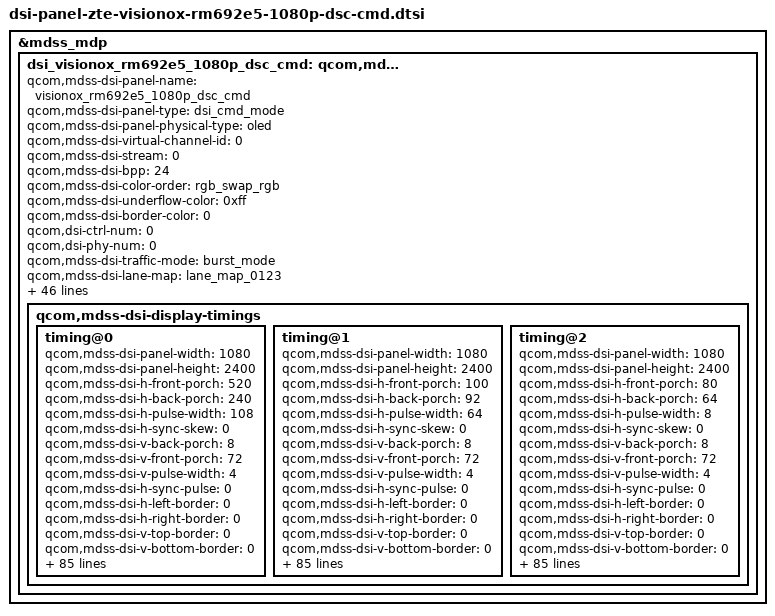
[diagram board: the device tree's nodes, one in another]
&mdss_mdp {
	dsi_visionox_rm692e5_1080p_dsc_cmd: qcom,mdss_dsi_visionox_rm692e5_1080p_dsc_cmd {
		qcom,mdss-dsi-panel-name =
				"visionox_rm692e5_1080p_dsc_cmd";
		qcom,mdss-dsi-panel-type = "dsi_cmd_mode";
		qcom,mdss-dsi-panel-physical-type = "oled";
		qcom,mdss-dsi-virtual-channel-id = <0>;
		qcom,mdss-dsi-stream = <0>;
		qcom,mdss-dsi-bpp = <24>;
		qcom,mdss-dsi-color-order = "rgb_swap_rgb";
		qcom,mdss-dsi-underflow-color = <0xff>;
		qcom,mdss-dsi-border-color = <0>;
		qcom,dsi-ctrl-num = <0>;
		qcom,dsi-phy-num = <0>;
		qcom,mdss-dsi-traffic-mode = "burst_mode";
		qcom,mdss-dsi-lane-map = "lane_map_0123";
		qcom,mdss-dsi-bllp-eof-power-mode;
		qcom,mdss-dsi-bllp-power-mode;
		qcom,mdss-dsi-lane-0-state;
		qcom,mdss-dsi-lane-1-state;
		qcom,mdss-dsi-lane-2-state;
		qcom,mdss-dsi-lane-3-state;
		qcom,mdss-dsi-lp11-init;
		qcom,mdss-dsi-tx-eot-append;
		qcom,mdss-dsi-dma-trigger = "trigger_sw";
		qcom,mdss-dsi-mdp-trigger = "none";
		qcom,mdss-dsi-reset-sequence = <1 10>, <0 10>, <1 50>;
		qcom,mdss-dsi-te-pin-select = <1>;
		qcom,mdss-dsi-te-dcs-command = <1>;
		qcom,mdss-dsi-te-check-enable;
		qcom,mdss-dsi-te-using-te-pin;
		qcom,mdss-dsi-bl-min-level = <1>;
		qcom,mdss-dsi-bl-max-level = <2047>;
		qcom,mdss-dsi-bl-pmic-control-type = "bl_ctrl_dcs";
		qcom,mdss-dsi-panel-hdr-enabled;
		qcom,mdss-dsi-panel-hdr-color-primaries = <14500 15500 34015
			15980 13030 34670 6950 2565>;
		qcom,mdss-dsi-panel-peak-brightness = <6680000>;
		qcom,mdss-dsi-panel-blackness-level = <20>;
		qcom,mdss-pan-physical-width-dimension = <69>;
		qcom,mdss-pan-physical-height-dimension = <155>;
		qcom,bl-dsc-cmd-state = "dsi_lp_mode";
		qcom,mdss-dsi-display-timings {
			timing@0{
				qcom,mdss-dsi-panel-width = <1080>;
				qcom,mdss-dsi-panel-height = <2400>;
				qcom,mdss-dsi-h-front-porch = <520>;
				qcom,mdss-dsi-h-back-porch = <240>;
				qcom,mdss-dsi-h-pulse-width = <108>;
				qcom,mdss-dsi-h-sync-skew = <0>;
				qcom,mdss-dsi-v-back-porch = <8>;
				qcom,mdss-dsi-v-front-porch = <72>;
				qcom,mdss-dsi-v-pulse-width = <4>;
				qcom,mdss-dsi-h-sync-pulse = <0>;
				qcom,mdss-dsi-h-left-border = <0>;
				qcom,mdss-dsi-h-right-border = <0>;
				qcom,mdss-dsi-v-top-border = <0>;
				qcom,mdss-dsi-v-bottom-border = <0>;
				qcom,mdss-dsi-panel-framerate = <60>;
				qcom,mdss-dsi-on-command = [
					/*dynamic elvss for ST IC*/
					15 01 00 00 00 00 02 FE 40
					15 01 00 00 00 00 02 B3 4F
					15 01 00 00 00 00 02 FE 26
					15 01 00 00 00 00 02 18 4C
					15 01 00 00 00 00 02 19 41
					15 01 00 00 00 00 02 A4 21
					15 01 00 00 00 00 02 A5 21
					15 01 00 00 00 00 02 1d 29
					15 01 00 00 00 00 02 FE 41
					15 01 00 00 00 00 02 D6 04
					15 01 00 00 00 00 02 FE 00
					39 01 00 00 00 00 80 77 37 37 37 37 37 37 37 37 39
					   3C 3F 37 37 37 37 37 37 37 37 39 3C 3F 37 37 37
					   37 37 37 37 37 39 3C 3F 37 37 37 37 37 37 37 37
					   39 3C 3F 2B 2B 2B 2B 2B 2B 2B 2B 39 3C 3F 2B 2B
					   2B 2B 2B 2B 2B 2B 39 3C 3F 2B 2B 2B 2B 2B 2B 2B
					   2B 39 3C 3F 2B 2B 2B 2B 2B 2B 2B 2B 39 3C 3F 31
					   31 31 31 31 31 31 31 33 39 3C 31 31 31 31 31 31
					   31 31 33 39 3C 31 31 31 31 31 31 31 31 33 39 3C
					   31 31 31 31 31 31
					39 01 00 00 00 00 80 78 31 31 33 39 3C 2B 2B 2B 2B
    				   2B 2B 2B 2B 33 39 3C 2B 2B 2B 2B 2B 2B 2B 2B 33
					   39 3C 2B 2B 2B 2B 2B 2B 2B 2B 33 39 3C 2B 2B 2B
					   2B 2B 2B 2B 2B 33 39 3C 37 37 37 37 37 37 37 37
					   39 3C 3F 37 37 37 37 37 37 37 37 39 3C 3F 37 37
					   37 37 37 37 37 37 39 3C 3F 37 37 37 37 37 37 37
					   37 39 3C 3F 2B 2B 2B 2B 2B 2B 2B 2B 39 3C 3F 2B
					   2B 2B 2B 2B 2B 2B 2B 39 3C 3F 2B 2B 2B 2B 2B 2B
					   2B 2B 39 3C 3F 2B
					39 01 00 00 00 00 80 78 2B 2B 2B 2B 2B 2B 2B 39 3C
					   3F 31 31 31 31 31 31 31 31 33 39 3C 31 31 31 31
					   31 31 31 31 33 39 3C 31 31 31 31 31 31 31 31 33
					   39 3C 31 31 31 31 31 31 31 31 33 39 3C 2B 2B 2B
					   2B 2B 2B 2B 2B 33 39 3C 2B 2B 2B 2B 2B 2B 2B 2B
					   33 39 3C 2B 2B 2B 2B 2B 2B 2B 2B 33 39 3C 2B 2B
					   2B 2B 2B 2B 2B 2B 33 39 3C 1F 1F 1F 1F 1F 1F 1F
					   1F 21 21 17 1F 1F 1F 1F 1F 1F 1F 1F 21 21 17 1F
					   1F 1F 1F 1F 1F 1F
					39 01 00 00 00 00 80 78 1F 21 21 17 1F 1F 1F 1F 1F
					   1F 1F 1F 21 21 17 1F 1F 1F 1F 1F 1F 1F 1F 21 21
					   17 1F 1F 1F 1F 1F 1F 1F 1F 21 21 17 1F 1F 1F 1F
					   1F 1F 1F 1F 21 21 17 1F 1F 1F 1F 1F 1F 1F 1F 21
					   21 17 1F 1F 1F 1F 1F 1F 1F 1F 21 21 17 1F 1F 1F
					   1F 1F 1F 1F 1F 21 21 17 1F 1F 1F 1F 1F 1F 1F 1F
					   21 21 17 1F 1F 1F 1F 1F 1F 1F 1F 21 21 17 1F 1F
					   1F 1F 1F 1F 1F 1F 21 21 17 1F 1F 1F 1F 1F 1F 1F
					   1F 21 21 17 1F 1F
					39 01 00 00 00 00 15 78 1F 1F 1F 1F 1F 1F 21 21 17
					   1F 1F 1F 1F 1F 1F 1F 1F 21 21 17
					15 01 00 00 00 00 02 FE 41
					15 01 00 00 00 00 02 D6 00
					/* ACL code */
					15 01 00 00 00 00 02 FE 00
					15 01 00 00 00 00 02 55 00
					15 01 00 00 00 00 02 FE 34
					15 01 00 00 00 00 02 47 03
					15 01 00 00 00 00 02 48 00
					15 01 00 00 00 00 02 00 00
					15 01 00 00 00 00 02 FE 34
					15 01 00 00 00 00 02 9F 38
					15 01 00 00 00 00 02 A0 04
					15 01 00 00 00 00 02 1E 00
					15 01 00 00 00 00 02 1F 00
					15 01 00 00 00 00 02 20 00
					15 01 00 00 00 00 02 22 00
					15 01 00 00 00 00 02 21 70
					15 01 00 00 00 00 02 23 F8
					15 01 00 00 00 00 02 24 77
					15 01 00 00 00 00 02 25 F8
					15 01 00 00 00 00 02 26 F8
					15 01 00 00 00 00 02 2F 00
					15 01 00 00 00 00 02 30 00
					15 01 00 00 00 00 02 31 00
					15 01 00 00 00 00 02 32 00
					15 01 00 00 00 00 02 33 00
					15 01 00 00 00 00 02 34 00
					15 01 00 00 00 00 02 35 00
					15 01 00 00 00 00 02 36 4C
					15 01 00 00 00 00 02 37 00
					15 01 00 00 00 00 02 38 E9
					15 01 00 00 00 00 02 39 01
					15 01 00 00 00 00 02 3A 53
					15 01 00 00 00 00 02 3B 00
					15 01 00 00 00 00 02 3D 00
					15 01 00 00 00 00 02 3F 00
					15 01 00 00 00 00 02 40 00
					15 01 00 00 00 00 02 41 00
					15 01 00 00 00 00 02 42 00
					/* P3 */
					15 01 00 00 00 00 02 FE 12
 					15 01 00 00 05 00 02 83 10
					/*init code*/
					15 01 00 00 00 00 02 FE 40
					15 01 00 00 00 00 02 BD 00
					15 01 00 00 00 00 02 FE A1
					15 01 00 00 00 00 02 CD 6B
					15 01 00 00 00 00 02 CE BB
					15 01 00 00 00 00 02 FE D1
					15 01 00 00 00 00 02 B4 01
					15 01 00 00 00 00 02 FE 38
					15 01 00 00 00 00 02 17 0F
					15 01 00 00 00 00 02 18 0F
					15 01 00 00 00 00 02 FE 00
					15 01 00 00 00 00 02 FA 01
					15 01 00 00 00 00 02 C2 08
					15 01 00 00 00 00 02 35 00
					39 01 00 00 00 00 03 51 00 00
					05 01 00 00 50 00 02 11 00
					05 01 00 00 0A 00 02 29 00];
				qcom,mdss-dsi-off-command = [
					05 01 00 00 C8 00 02 28 00
					05 01 00 00 0A 00 02 10 00
				];
				qcom,mdss-dsi-on-command-state = "dsi_lp_mode";
				qcom,mdss-dsi-off-command-state = "dsi_lp_mode";
				qcom,mdss-dsi-lp1-command = [
					15 01 00 00 00 00 02 FE 40
					15 01 00 00 00 00 02 B3 50
					15 01 00 00 00 00 02 FE A0
					15 01 00 00 00 00 02 25 C0
					15 01 00 00 00 00 02 FE 00
					05 01 00 00 00 00 02 39 00
					15 01 00 00 00 00 02 FE 00
				];
				qcom,mdss-dsi-lp1-command-state =
					"dsi_lp_mode";
				qcom,mdss-dsi-nolp-command = [
					39 01 00 00 00 00 02 FE 00
					39 01 00 00 00 00 03 51 00 00
					05 01 00 00 00 00 02 38 00
					39 01 00 00 00 00 02 FE A0
					05 01 00 00 00 00 02 25 40
					39 01 00 00 00 00 02 FE 00
				];
				qcom,mdss-dsi-nolp-command-state =
					"dsi_lp_mode";
				qcom,mdss-dsi-timing-switch-command = [
					15 01 00 00 00 00 02 FE 40
					15 01 00 00 00 00 02 BD 00
					15 01 00 00 00 00 02 FE 00
				];
				qcom,mdss-dsi-timing-switch-command-state =
					"dsi_lp_mode";
				qcom,compression-mode = "dsc";
				qcom,mdss-dsc-slice-height = <20>;
				qcom,mdss-dsc-slice-width = <540>;
				qcom,mdss-dsc-slice-per-pkt = <2>;
				qcom,mdss-dsc-bit-per-component = <8>;
				qcom,mdss-dsc-bit-per-pixel = <8>;
				qcom,mdss-dsc-block-prediction-enable;
			};
			timing@1{
				qcom,mdss-dsi-panel-width = <1080>;
				qcom,mdss-dsi-panel-height = <2400>;
				qcom,mdss-dsi-h-front-porch = <100>;
				qcom,mdss-dsi-h-back-porch = <92>;
				qcom,mdss-dsi-h-pulse-width = <64>;
				qcom,mdss-dsi-h-sync-skew = <0>;
				qcom,mdss-dsi-v-back-porch = <8>;
				qcom,mdss-dsi-v-front-porch = <72>;
				qcom,mdss-dsi-v-pulse-width = <4>;
				qcom,mdss-dsi-h-sync-pulse = <0>;
				qcom,mdss-dsi-h-left-border = <0>;
				qcom,mdss-dsi-h-right-border = <0>;
				qcom,mdss-dsi-v-top-border = <0>;
				qcom,mdss-dsi-v-bottom-border = <0>;
				qcom,mdss-dsi-panel-framerate = <120>;
				qcom,mdss-dsi-on-command = [
					/*dynamic elvss for ST IC*/
					15 01 00 00 00 00 02 FE 40
					15 01 00 00 00 00 02 B3 4F
					15 01 00 00 00 00 02 FE 26
					15 01 00 00 00 00 02 18 4C
					15 01 00 00 00 00 02 19 41
					15 01 00 00 00 00 02 A4 21
					15 01 00 00 00 00 02 A5 21
					15 01 00 00 00 00 02 1d 29
					15 01 00 00 00 00 02 FE 41
					15 01 00 00 00 00 02 D6 04
					15 01 00 00 00 00 02 FE 00
					39 01 00 00 00 00 80 77 37 37 37 37 37 37 37 37 39
					   3C 3F 37 37 37 37 37 37 37 37 39 3C 3F 37 37 37
					   37 37 37 37 37 39 3C 3F 37 37 37 37 37 37 37 37
					   39 3C 3F 2B 2B 2B 2B 2B 2B 2B 2B 39 3C 3F 2B 2B
					   2B 2B 2B 2B 2B 2B 39 3C 3F 2B 2B 2B 2B 2B 2B 2B
					   2B 39 3C 3F 2B 2B 2B 2B 2B 2B 2B 2B 39 3C 3F 31
					   31 31 31 31 31 31 31 33 39 3C 31 31 31 31 31 31
					   31 31 33 39 3C 31 31 31 31 31 31 31 31 33 39 3C
					   31 31 31 31 31 31
					39 01 00 00 00 00 80 78 31 31 33 39 3C 2B 2B 2B 2B
    				   2B 2B 2B 2B 33 39 3C 2B 2B 2B 2B 2B 2B 2B 2B 33
					   39 3C 2B 2B 2B 2B 2B 2B 2B 2B 33 39 3C 2B 2B 2B
					   2B 2B 2B 2B 2B 33 39 3C 37 37 37 37 37 37 37 37
					   39 3C 3F 37 37 37 37 37 37 37 37 39 3C 3F 37 37
					   37 37 37 37 37 37 39 3C 3F 37 37 37 37 37 37 37
					   37 39 3C 3F 2B 2B 2B 2B 2B 2B 2B 2B 39 3C 3F 2B
					   2B 2B 2B 2B 2B 2B 2B 39 3C 3F 2B 2B 2B 2B 2B 2B
					   2B 2B 39 3C 3F 2B
					39 01 00 00 00 00 80 78 2B 2B 2B 2B 2B 2B 2B 39 3C
					   3F 31 31 31 31 31 31 31 31 33 39 3C 31 31 31 31
					   31 31 31 31 33 39 3C 31 31 31 31 31 31 31 31 33
					   39 3C 31 31 31 31 31 31 31 31 33 39 3C 2B 2B 2B
					   2B 2B 2B 2B 2B 33 39 3C 2B 2B 2B 2B 2B 2B 2B 2B
					   33 39 3C 2B 2B 2B 2B 2B 2B 2B 2B 33 39 3C 2B 2B
					   2B 2B 2B 2B 2B 2B 33 39 3C 1F 1F 1F 1F 1F 1F 1F
					   1F 21 21 17 1F 1F 1F 1F 1F 1F 1F 1F 21 21 17 1F
					   1F 1F 1F 1F 1F 1F
					39 01 00 00 00 00 80 78 1F 21 21 17 1F 1F 1F 1F 1F
					   1F 1F 1F 21 21 17 1F 1F 1F 1F 1F 1F 1F 1F 21 21
					   17 1F 1F 1F 1F 1F 1F 1F 1F 21 21 17 1F 1F 1F 1F
					   1F 1F 1F 1F 21 21 17 1F 1F 1F 1F 1F 1F 1F 1F 21
					   21 17 1F 1F 1F 1F 1F 1F 1F 1F 21 21 17 1F 1F 1F
					   1F 1F 1F 1F 1F 21 21 17 1F 1F 1F 1F 1F 1F 1F 1F
					   21 21 17 1F 1F 1F 1F 1F 1F 1F 1F 21 21 17 1F 1F
					   1F 1F 1F 1F 1F 1F 21 21 17 1F 1F 1F 1F 1F 1F 1F
					   1F 21 21 17 1F 1F
					39 01 00 00 00 00 15 78 1F 1F 1F 1F 1F 1F 21 21 17
					   1F 1F 1F 1F 1F 1F 1F 1F 21 21 17
					15 01 00 00 00 00 02 FE 41
					15 01 00 00 00 00 02 D6 00
					/* ACL code */
					15 01 00 00 00 00 02 FE 00
					15 01 00 00 00 00 02 55 00
					15 01 00 00 00 00 02 FE 34
					15 01 00 00 00 00 02 47 03
					15 01 00 00 00 00 02 48 00
					15 01 00 00 00 00 02 00 00
					15 01 00 00 00 00 02 FE 34
					15 01 00 00 00 00 02 9F 38
					15 01 00 00 00 00 02 A0 04
					15 01 00 00 00 00 02 1E 00
					15 01 00 00 00 00 02 1F 00
					15 01 00 00 00 00 02 20 00
					15 01 00 00 00 00 02 22 00
					15 01 00 00 00 00 02 21 70
					15 01 00 00 00 00 02 23 F8
					15 01 00 00 00 00 02 24 77
					15 01 00 00 00 00 02 25 F8
					15 01 00 00 00 00 02 26 F8
					15 01 00 00 00 00 02 2F 00
					15 01 00 00 00 00 02 30 00
					15 01 00 00 00 00 02 31 00
					15 01 00 00 00 00 02 32 00
					15 01 00 00 00 00 02 33 00
					15 01 00 00 00 00 02 34 00
					15 01 00 00 00 00 02 35 00
					15 01 00 00 00 00 02 36 4C
					15 01 00 00 00 00 02 37 00
					15 01 00 00 00 00 02 38 E9
					15 01 00 00 00 00 02 39 01
					15 01 00 00 00 00 02 3A 53
					15 01 00 00 00 00 02 3B 00
					15 01 00 00 00 00 02 3D 00
					15 01 00 00 00 00 02 3F 00
					15 01 00 00 00 00 02 40 00
					15 01 00 00 00 00 02 41 00
					15 01 00 00 00 00 02 42 00
					/* P3 */
					15 01 00 00 00 00 02 FE 12
 					15 01 00 00 05 00 02 83 10
					/*init code*/
					15 01 00 00 00 00 02 FE 40
					15 01 00 00 00 00 02 BD 06
					15 01 00 00 00 00 02 FE A1
					15 01 00 00 00 00 02 CD 6B
					15 01 00 00 00 00 02 CE BB
					15 01 00 00 00 00 02 FE D1
					15 01 00 00 00 00 02 B4 01
					15 01 00 00 00 00 02 FE 38
					15 01 00 00 00 00 02 17 0F
					15 01 00 00 00 00 02 18 0F
					15 01 00 00 00 00 02 FE 00
					15 01 00 00 00 00 02 FA 01
					15 01 00 00 00 00 02 C2 08
					15 01 00 00 00 00 02 35 00
					39 01 00 00 00 00 03 51 00 00
					05 01 00 00 50 00 02 11 00
					05 01 00 00 0A 00 02 29 00];
				qcom,mdss-dsi-off-command = [
					05 01 00 00 C8 00 02 28 00
					05 01 00 00 0A 00 02 10 00
				];
				qcom,mdss-dsi-on-command-state = "dsi_lp_mode";
				qcom,mdss-dsi-off-command-state = "dsi_lp_mode";
				qcom,mdss-dsi-lp1-command = [
					15 01 00 00 00 00 02 FE 40
					15 01 00 00 00 00 02 B3 50
					15 01 00 00 00 00 02 FE A0
					15 01 00 00 00 00 02 25 C0
					15 01 00 00 00 00 02 FE 00
					05 01 00 00 00 00 02 39 00
					15 01 00 00 00 00 02 FE 00
				];
				qcom,mdss-dsi-lp1-command-state =
					"dsi_lp_mode";
				qcom,mdss-dsi-nolp-command = [
					39 01 00 00 00 00 02 FE 00
					39 01 00 00 00 00 03 51 00 00
					05 01 00 00 00 00 02 38 00
					39 01 00 00 00 00 02 FE A0
					05 01 00 00 00 00 02 25 40
					39 01 00 00 00 00 02 FE 00
				];
				qcom,mdss-dsi-nolp-command-state =
					"dsi_lp_mode";
				qcom,mdss-dsi-timing-switch-command = [
					15 01 00 00 00 00 02 FE 40
					15 01 00 00 00 00 02 BD 06
					15 01 00 00 00 00 02 FE 00
				];
				qcom,mdss-dsi-timing-switch-command-state =
					"dsi_lp_mode";
				qcom,compression-mode = "dsc";
				qcom,mdss-dsc-slice-height = <20>;
				qcom,mdss-dsc-slice-width = <540>;
				qcom,mdss-dsc-slice-per-pkt = <2>;
				qcom,mdss-dsc-bit-per-component = <8>;
				qcom,mdss-dsc-bit-per-pixel = <8>;
				qcom,mdss-dsc-block-prediction-enable;
			};
			timing@2{
				qcom,mdss-dsi-panel-width = <1080>;
				qcom,mdss-dsi-panel-height = <2400>;
				qcom,mdss-dsi-h-front-porch = <80>;
				qcom,mdss-dsi-h-back-porch = <64>;
				qcom,mdss-dsi-h-pulse-width = <8>;
				qcom,mdss-dsi-h-sync-skew = <0>;
				qcom,mdss-dsi-v-back-porch = <8>;
				qcom,mdss-dsi-v-front-porch = <72>;
				qcom,mdss-dsi-v-pulse-width = <4>;
				qcom,mdss-dsi-h-sync-pulse = <0>;
				qcom,mdss-dsi-h-left-border = <0>;
				qcom,mdss-dsi-h-right-border = <0>;
				qcom,mdss-dsi-v-top-border = <0>;
				qcom,mdss-dsi-v-bottom-border = <0>;
				qcom,mdss-dsi-panel-framerate = <144>;
				qcom,mdss-dsi-on-command = [
					/*dynamic elvss for ST IC*/
					15 01 00 00 00 00 02 FE 40
					15 01 00 00 00 00 02 B3 4F
					15 01 00 00 00 00 02 FE 26
					15 01 00 00 00 00 02 18 4C
					15 01 00 00 00 00 02 19 41
					15 01 00 00 00 00 02 A4 21
					15 01 00 00 00 00 02 A5 21
					15 01 00 00 00 00 02 1d 29
					15 01 00 00 00 00 02 FE 41
					15 01 00 00 00 00 02 D6 04
					15 01 00 00 00 00 02 FE 00
					39 01 00 00 00 00 80 77 37 37 37 37 37 37 37 37 39
					   3C 3F 37 37 37 37 37 37 37 37 39 3C 3F 37 37 37
					   37 37 37 37 37 39 3C 3F 37 37 37 37 37 37 37 37
					   39 3C 3F 2B 2B 2B 2B 2B 2B 2B 2B 39 3C 3F 2B 2B
					   2B 2B 2B 2B 2B 2B 39 3C 3F 2B 2B 2B 2B 2B 2B 2B
					   2B 39 3C 3F 2B 2B 2B 2B 2B 2B 2B 2B 39 3C 3F 31
					   31 31 31 31 31 31 31 33 39 3C 31 31 31 31 31 31
					   31 31 33 39 3C 31 31 31 31 31 31 31 31 33 39 3C
					   31 31 31 31 31 31
					39 01 00 00 00 00 80 78 31 31 33 39 3C 2B 2B 2B 2B
    				   2B 2B 2B 2B 33 39 3C 2B 2B 2B 2B 2B 2B 2B 2B 33
					   39 3C 2B 2B 2B 2B 2B 2B 2B 2B 33 39 3C 2B 2B 2B
					   2B 2B 2B 2B 2B 33 39 3C 37 37 37 37 37 37 37 37
					   39 3C 3F 37 37 37 37 37 37 37 37 39 3C 3F 37 37
					   37 37 37 37 37 37 39 3C 3F 37 37 37 37 37 37 37
					   37 39 3C 3F 2B 2B 2B 2B 2B 2B 2B 2B 39 3C 3F 2B
					   2B 2B 2B 2B 2B 2B 2B 39 3C 3F 2B 2B 2B 2B 2B 2B
					   2B 2B 39 3C 3F 2B
					39 01 00 00 00 00 80 78 2B 2B 2B 2B 2B 2B 2B 39 3C
					   3F 31 31 31 31 31 31 31 31 33 39 3C 31 31 31 31
					   31 31 31 31 33 39 3C 31 31 31 31 31 31 31 31 33
					   39 3C 31 31 31 31 31 31 31 31 33 39 3C 2B 2B 2B
					   2B 2B 2B 2B 2B 33 39 3C 2B 2B 2B 2B 2B 2B 2B 2B
					   33 39 3C 2B 2B 2B 2B 2B 2B 2B 2B 33 39 3C 2B 2B
					   2B 2B 2B 2B 2B 2B 33 39 3C 1F 1F 1F 1F 1F 1F 1F
					   1F 21 21 17 1F 1F 1F 1F 1F 1F 1F 1F 21 21 17 1F
					   1F 1F 1F 1F 1F 1F
					39 01 00 00 00 00 80 78 1F 21 21 17 1F 1F 1F 1F 1F
					   1F 1F 1F 21 21 17 1F 1F 1F 1F 1F 1F 1F 1F 21 21
					   17 1F 1F 1F 1F 1F 1F 1F 1F 21 21 17 1F 1F 1F 1F
					   1F 1F 1F 1F 21 21 17 1F 1F 1F 1F 1F 1F 1F 1F 21
					   21 17 1F 1F 1F 1F 1F 1F 1F 1F 21 21 17 1F 1F 1F
					   1F 1F 1F 1F 1F 21 21 17 1F 1F 1F 1F 1F 1F 1F 1F
					   21 21 17 1F 1F 1F 1F 1F 1F 1F 1F 21 21 17 1F 1F
					   1F 1F 1F 1F 1F 1F 21 21 17 1F 1F 1F 1F 1F 1F 1F
					   1F 21 21 17 1F 1F
					39 01 00 00 00 00 15 78 1F 1F 1F 1F 1F 1F 21 21 17
					   1F 1F 1F 1F 1F 1F 1F 1F 21 21 17
					15 01 00 00 00 00 02 FE 41
					15 01 00 00 00 00 02 D6 00
					/* ACL code */
					15 01 00 00 00 00 02 FE 00
					15 01 00 00 00 00 02 55 00
					15 01 00 00 00 00 02 FE 34
					15 01 00 00 00 00 02 47 03
					15 01 00 00 00 00 02 48 00
					15 01 00 00 00 00 02 00 00
					15 01 00 00 00 00 02 FE 34
					15 01 00 00 00 00 02 9F 38
					15 01 00 00 00 00 02 A0 04
					15 01 00 00 00 00 02 1E 00
					15 01 00 00 00 00 02 1F 00
					15 01 00 00 00 00 02 20 00
					15 01 00 00 00 00 02 22 00
					15 01 00 00 00 00 02 21 70
					15 01 00 00 00 00 02 23 F8
					15 01 00 00 00 00 02 24 77
					15 01 00 00 00 00 02 25 F8
					15 01 00 00 00 00 02 26 F8
					15 01 00 00 00 00 02 2F 00
					15 01 00 00 00 00 02 30 00
					15 01 00 00 00 00 02 31 00
					15 01 00 00 00 00 02 32 00
					15 01 00 00 00 00 02 33 00
					15 01 00 00 00 00 02 34 00
					15 01 00 00 00 00 02 35 00
					15 01 00 00 00 00 02 36 4C
					15 01 00 00 00 00 02 37 00
					15 01 00 00 00 00 02 38 E9
					15 01 00 00 00 00 02 39 01
					15 01 00 00 00 00 02 3A 53
					15 01 00 00 00 00 02 3B 00
					15 01 00 00 00 00 02 3D 00
					15 01 00 00 00 00 02 3F 00
					15 01 00 00 00 00 02 40 00
					15 01 00 00 00 00 02 41 00
					15 01 00 00 00 00 02 42 00
					/* P3 */
					15 01 00 00 00 00 02 FE 12
 					15 01 00 00 05 00 02 83 10
					/*init code*/
					15 01 00 00 00 00 02 FE 40
					15 01 00 00 00 00 02 BD 07
					15 01 00 00 00 00 02 FE A1
					15 01 00 00 00 00 02 CD 6B
					15 01 00 00 00 00 02 CE BB
					15 01 00 00 00 00 02 FE D1
					15 01 00 00 00 00 02 B4 01
					15 01 00 00 00 00 02 FE 38
					15 01 00 00 00 00 02 17 0F
					15 01 00 00 00 00 02 18 0F
					15 01 00 00 00 00 02 FE 00
					15 01 00 00 00 00 02 FA 01
					15 01 00 00 00 00 02 C2 08
					15 01 00 00 00 00 02 35 00
					39 01 00 00 00 00 03 51 00 00
					05 01 00 00 50 00 02 11 00
					05 01 00 00 0A 00 02 29 00];
				qcom,mdss-dsi-off-command = [
					05 01 00 00 32 00 02 28 00
					05 01 00 00 20 00 02 10 00
				];
				qcom,mdss-dsi-on-command-state = "dsi_lp_mode";
				qcom,mdss-dsi-off-command-state = "dsi_lp_mode";
				qcom,mdss-dsi-lp1-command = [
					15 01 00 00 00 00 02 FE 40
					15 01 00 00 00 00 02 B3 50
					15 01 00 00 00 00 02 FE A0
					15 01 00 00 00 00 02 25 C0
					15 01 00 00 00 00 02 FE 00
					05 01 00 00 00 00 02 39 00
					15 01 00 00 00 00 02 FE 00
				];
				qcom,mdss-dsi-lp1-command-state =
					"dsi_lp_mode";
				qcom,mdss-dsi-nolp-command = [
					39 01 00 00 00 00 02 FE 00
					39 01 00 00 00 00 03 51 00 00
					05 01 00 00 00 00 02 38 00
					39 01 00 00 00 00 02 FE A0
					05 01 00 00 00 00 02 25 40
					39 01 00 00 00 00 02 FE 00
				];
				qcom,mdss-dsi-nolp-command-state =
					"dsi_lp_mode";
				qcom,mdss-dsi-timing-switch-command = [
					15 01 00 00 00 00 02 FE 40
					15 01 00 00 00 00 02 BD 07
					15 01 00 00 00 00 02 FE 00
				];
				qcom,mdss-dsi-timing-switch-command-state =
					"dsi_lp_mode";
				qcom,compression-mode = "dsc";
				qcom,mdss-dsc-slice-height = <20>;
				qcom,mdss-dsc-slice-width = <540>;
				qcom,mdss-dsc-slice-per-pkt = <2>;
				qcom,mdss-dsc-bit-per-component = <8>;
				qcom,mdss-dsc-bit-per-pixel = <8>;
				qcom,mdss-dsc-block-prediction-enable;
			};
		};
	};
};

/* zte dsip power supply */
&dsi_visionox_rm692e5_1080p_dsc_cmd {
	qcom,panel-supply-entries = <&dsi_panel_pwr_supply_no_labibb>;
	qcom,mdss-dsi-bl-pmic-control-type = "bl_ctrl_dcs";
	qcom,mdss-brightness-max-level = <2047>;
	qcom,mdss-dsi-bl-inverted-dbv;
	qcom,platform-reset-gpio = <&tlmm 133 0>;
	zte,disp_iovdd_en_gpio = <&tlmm 89 0>;
	qcom,ulps-enabled;
	qcom,dsi-select-clocks = "pll_byte_clk0", "pll_dsi_clk0";
	//qcom,mdss-dsi-panel-status-check-mode = "reg_read";
	//qcom,mdss-dsi-panel-status-command = [06 01 00 01 00 00 01 0a];
	//qcom,mdss-dsi-panel-status-command-state = "dsi_lp_mode";
	//qcom,mdss-dsi-panel-status-value = <0x9c>;
	//qcom,mdss-dsi-panel-status-read-length = <1>;
	//qcom,esd-check-enabled;
	qcom,mdss-dsi-display-timings {
		timing@0 {
			qcom,mdss-dsi-panel-phy-timings = [00 24 0A 0A 1A 18 0A
				0A 09 02 04 00 1E 0F];
			qcom,display-topology = <2 2 1>;
			qcom,default-topology-index = <0>;
			qcom,mdss-dsi-panel-clockrate = <1100000000>;
		};
		timing@1 {
			qcom,mdss-dsi-panel-phy-timings = [00 24 0A 0A 1A 18 0A
				0A 09 02 04 00 1E 0F];
			qcom,display-topology = <2 2 1>;
			qcom,default-topology-index = <0>;
			qcom,mdss-dsi-panel-clockrate = <1100100000>;
		};
		timing@2 {
			qcom,mdss-dsi-panel-phy-timings = [00 24 0A 0A 1A 18 0A
				0A 09 02 04 00 1E 0F];
			qcom,display-topology = <2 2 1>;
			qcom,default-topology-index = <0>;
			qcom,mdss-dsi-panel-clockrate = <1100200000>;
		};
	};
};

&dsi_visionox_rm692e5_1080p_dsc_cmd {
	qcom,mdss-dsi-display-timings {
		timing@0 {
			#include "dsi-panel-zte-visionox-rm692e5-common.dtsi"
		};
		timing@1 {
			#include "dsi-panel-zte-visionox-rm692e5-common.dtsi"
		};
		timing@2 {
			#include "dsi-panel-zte-visionox-rm692e5-common.dtsi"
		};
	};
};

/* LCD Features */
&dsi_visionox_rm692e5_1080p_dsc_cmd {
	/* zte disp feature */
	zte,hbm_enabled;
	zte,hdr_enabled;
	zte,fps_enabled;
	zte,acl_enabled;
	zte,aod_enabled;
	zte,lspot_enabled;
	//zte,curve_enabled;
	zte,color_space_enabled;
	//zte,lcm_backlight_curve_mode = "lcd_brightness_max_450_lux";
	zte,hbm_off_reg51_index = <2>;
	zte,hdr_brightness = <0xFFF>;
	zte,aod-exit-delay-time = <150>;
	
	qcom,mdss-dsi-display-timings {
		timing@0 {
			zte,mdss-dsi-hbm-on-commands = [
				15 01 00 00 00 00 02 FE 00
				39 01 00 00 00 00 02 53 20
				39 01 00 00 00 00 03 51 0f ff
			];
			zte,mdss-dsi-hbm-off-commands = [
				15 01 00 00 00 00 02 FE 00
				39 01 00 00 00 00 02 53 20
				39 01 00 00 00 00 03 51 03 22
			];
			zte,mdss-dsi-aod-low-commands = [
				15 01 00 00 00 00 02 FE 00
				39 01 00 00 00 00 03 51 01 20
			];
			zte,mdss-dsi-aod-mid-commands = [
				15 01 00 00 00 00 02 FE 00
				39 01 00 00 00 00 03 51 07 ff
			];
			zte,mdss-dsi-aod-high-commands = [
				15 01 00 00 00 00 02 FE 00
				39 01 00 00 00 00 03 51 0f ff
			];
			zte,mdss-dsi-restore-bl-commands = [
				15 01 00 00 00 00 02 FE 00
				39 01 00 00 00 00 03 51 03 FF
			];
			zte,mdss-dsi-acl-off-commands = [
				15 01 00 00 00 00 02 FE 00
				15 01 00 00 00 00 02 55 00
			];
			zte,mdss-dsi-acl-low-commands = [
				15 01 00 00 00 00 02 FE 00
				15 01 00 00 00 00 02 55 01
			];
			zte,mdss-dsi-acl-mid-commands = [
				15 01 00 00 00 00 02 FE 00
				15 01 00 00 00 00 02 55 02
			];
			zte,mdss-dsi-acl-high-commands = [
				15 01 00 00 00 00 02 FE 00
				15 01 00 00 00 00 02 55 03
			];
			zte,mdss-dsi-aod-off-hbm-on-commands = [
				39 01 00 00 00 00 02 FE 00
				05 01 00 00 00 00 01 38
				15 01 00 00 00 00 02 FE 00
				39 01 00 00 00 00 02 53 20
				39 01 00 00 00 00 03 51 0f ff
			];
			zte,mdss-dsi-hbm-off-aod-on-commands = [
			    39 01 00 00 00 00 02 FE 00
				39 01 00 00 00 00 03 51 00 00
				05 01 00 00 00 00 01 39
				39 01 00 00 00 00 03 51 01 20
			];
			zte,mdss-dsi-reg-read-commands = [
			    06 01 00 00 00 00 01 A0
			];
            zte,mdss-dsi-dim-on-commands = [
			    15 01 00 00 00 00 02 FE 00
				15 01 00 00 00 00 02 53 28
			];
			zte,mdss-dsi-hbm-on-commands-state = "dsi_hs_mode";
			zte,mdss-dsi-hbm-off-commands-state = "dsi_hs_mode";
			zte,mdss-dsi-aod-low-commands-state = "dsi_hs_mode";
			zte,mdss-dsi-aod-mid-commands-state = "dsi_hs_mode";
			zte,mdss-dsi-aod-high-commands-state = "dsi_hs_mode";
			zte,mdss-dsi-restore-bl-commands-state = "dsi_hs_mode";
			zte,mdss-dsi-acl-off-commands-state = "dsi_lp_mode";
			zte,mdss-dsi-acl-low-commands-state = "dsi_lp_mode";
			zte,mdss-dsi-acl-mid-commands-state = "dsi_lp_mode";
			zte,mdss-dsi-acl-high-commands-state = "dsi_lp_mode";
			zte,mdss-dsi-aod-off-hbm-on-commands-state = "dsi_lp_mode";
			zte,mdss-dsi-reg-read-commands-state = "dsi_lp_mode";
			zte,mdss-dsi-hbm-off-aod-on-commands-state = "dsi_lp_mode";
			zte,mdss-dsi-dim-on-commands-state = "dsi_hs_mode";
		};
		timing@1 {
			zte,mdss-dsi-hbm-on-commands = [
				15 01 00 00 00 00 02 FE 00
				39 01 00 00 00 00 02 53 20
				39 01 00 00 00 00 03 51 0f ff
			];
			zte,mdss-dsi-hbm-off-commands = [
				15 01 00 00 00 00 02 FE 00
				39 01 00 00 00 00 02 53 20
				39 01 00 00 00 00 03 51 03 22
			];
			zte,mdss-dsi-aod-low-commands = [
				15 01 00 00 00 00 02 FE 00
				39 01 00 00 00 00 03 51 01 20
			];
			zte,mdss-dsi-aod-mid-commands = [
				15 01 00 00 00 00 02 FE 00
				39 01 00 00 00 00 03 51 07 ff
			];
			zte,mdss-dsi-aod-high-commands = [
				15 01 00 00 00 00 02 FE 00
				39 01 00 00 00 00 03 51 0f ff
			];
			zte,mdss-dsi-restore-bl-commands = [
				15 01 00 00 00 00 02 FE 00
				39 01 00 00 00 00 03 51 03 FF
			];
			zte,mdss-dsi-acl-off-commands = [
				15 01 00 00 00 00 02 FE 00
				15 01 00 00 00 00 02 55 00
			];
			zte,mdss-dsi-acl-low-commands = [
				15 01 00 00 00 00 02 FE 00
				15 01 00 00 00 00 02 55 01
			];
			zte,mdss-dsi-acl-mid-commands = [
				15 01 00 00 00 00 02 FE 00
				15 01 00 00 00 00 02 55 02
			];
			zte,mdss-dsi-acl-high-commands = [
				15 01 00 00 00 00 02 FE 00
				15 01 00 00 00 00 02 55 03
			];
			
			zte,mdss-dsi-aod-off-hbm-on-commands = [
				39 01 00 00 00 00 02 FE 00
				05 01 00 00 00 00 01 38
				15 01 00 00 00 00 02 FE 00
				39 01 00 00 00 00 02 53 20
				39 01 00 00 00 00 03 51 0f ff
			];
			zte,mdss-dsi-hbm-off-aod-on-commands = [
			    39 01 00 00 00 00 02 FE 00
				39 01 00 00 00 00 03 51 00 00
				05 01 00 00 00 00 01 39
				39 01 00 00 00 00 03 51 01 20
			];
			zte,mdss-dsi-reg-read-commands = [
			    06 01 00 00 00 00 01 A0
			];
			zte,mdss-dsi-dim-on-commands = [
			    15 01 00 00 00 00 02 FE 00
				15 01 00 00 00 00 02 53 28
			];
			zte,mdss-dsi-hbm-on-commands-state = "dsi_hs_mode";
			zte,mdss-dsi-hbm-off-commands-state = "dsi_hs_mode";
			zte,mdss-dsi-aod-low-commands-state = "dsi_hs_mode";
			zte,mdss-dsi-aod-mid-commands-state = "dsi_hs_mode";
			zte,mdss-dsi-aod-high-commands-state = "dsi_hs_mode";
			zte,mdss-dsi-restore-bl-commands-state = "dsi_hs_mode";
			zte,mdss-dsi-acl-off-commands-state = "dsi_lp_mode";
			zte,mdss-dsi-acl-low-commands-state = "dsi_lp_mode";
			zte,mdss-dsi-acl-mid-commands-state = "dsi_lp_mode";
			zte,mdss-dsi-acl-high-commands-state = "dsi_lp_mode";
			zte,mdss-dsi-aod-off-hbm-on-commands-state = "dsi_lp_mode";
			zte,mdss-dsi-reg-read-commands-state = "dsi_lp_mode";
			zte,mdss-dsi-hbm-off-aod-on-commands-state = "dsi_lp_mode";
			zte,mdss-dsi-dim-on-commands-state = "dsi_hs_mode";
		};
		timing@2 {
			zte,mdss-dsi-hbm-on-commands = [
				15 01 00 00 00 00 02 FE 00
				39 01 00 00 00 00 02 53 20
				39 01 00 00 00 00 03 51 0f ff
			];
			zte,mdss-dsi-hbm-off-commands = [
				15 01 00 00 00 00 02 FE 00
				39 01 00 00 00 00 02 53 20
				39 01 00 00 00 00 03 51 03 22
			];
			zte,mdss-dsi-aod-low-commands = [
				15 01 00 00 00 00 02 FE 00
				39 01 00 00 00 00 03 51 01 20
			];
			zte,mdss-dsi-aod-mid-commands = [
				15 01 00 00 00 00 02 FE 00
				39 01 00 00 00 00 03 51 07 ff
			];
			zte,mdss-dsi-aod-high-commands = [
				15 01 00 00 00 00 02 FE 00
				39 01 00 00 00 00 03 51 0f ff
			];
			zte,mdss-dsi-restore-bl-commands = [
				15 01 00 00 00 00 02 FE 00
				39 01 00 00 00 00 03 51 03 FF
			];
			zte,mdss-dsi-acl-off-commands = [
				15 01 00 00 00 00 02 FE 00
				15 01 00 00 00 00 02 55 00
			];
			zte,mdss-dsi-acl-low-commands = [
				15 01 00 00 00 00 02 FE 00
				15 01 00 00 00 00 02 55 01
			];
			zte,mdss-dsi-acl-mid-commands = [
				15 01 00 00 00 00 02 FE 00
				15 01 00 00 00 00 02 55 02
			];
			zte,mdss-dsi-acl-high-commands = [
				15 01 00 00 00 00 02 FE 00
				15 01 00 00 00 00 02 55 03
			];
			zte,mdss-dsi-aod-off-hbm-on-commands = [
				39 01 00 00 00 00 02 FE 00
				05 01 00 00 00 00 01 38
				15 01 00 00 00 00 02 FE 00
				39 01 00 00 00 00 02 53 20
				39 01 00 00 00 00 03 51 0f ff
			];
			zte,mdss-dsi-hbm-off-aod-on-commands = [
			    39 01 00 00 00 00 02 FE 00
				39 01 00 00 00 00 03 51 00 00
				05 01 00 00 00 00 01 39
				39 01 00 00 00 00 03 51 01 20
			];
			zte,mdss-dsi-reg-read-commands = [
			    06 01 00 00 00 00 01 A0
			];
			zte,mdss-dsi-dim-on-commands = [
			    15 01 00 00 00 00 02 FE 00
				15 01 00 00 00 00 02 53 28
			];
			zte,mdss-dsi-hbm-on-commands-state = "dsi_hs_mode";
			zte,mdss-dsi-hbm-off-commands-state = "dsi_hs_mode";
			zte,mdss-dsi-aod-low-commands-state = "dsi_hs_mode";
			zte,mdss-dsi-aod-mid-commands-state = "dsi_hs_mode";
			zte,mdss-dsi-aod-high-commands-state = "dsi_hs_mode";
			zte,mdss-dsi-restore-bl-commands-state = "dsi_hs_mode";
			zte,mdss-dsi-acl-off-commands-state = "dsi_lp_mode";
			zte,mdss-dsi-acl-low-commands-state = "dsi_lp_mode";
			zte,mdss-dsi-acl-mid-commands-state = "dsi_lp_mode";
			zte,mdss-dsi-acl-high-commands-state = "dsi_lp_mode";
			zte,mdss-dsi-aod-off-hbm-on-commands-state = "dsi_lp_mode";
			zte,mdss-dsi-reg-read-commands-state = "dsi_lp_mode";
			zte,mdss-dsi-hbm-off-aod-on-commands-state = "dsi_lp_mode";
			zte,mdss-dsi-dim-on-commands-state = "dsi_hs_mode";
		};
	};
};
